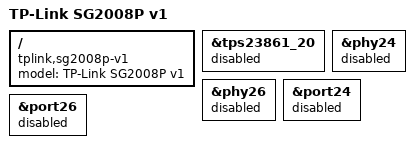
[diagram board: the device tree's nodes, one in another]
// SPDX-License-Identifier: GPL-2.0-or-later

#include "rtl8380_tplink_sg2xxx.dtsi"

/ {
	compatible = "tplink,sg2008p-v1", "realtek,rtl838x-soc";
	model = "TP-Link SG2008P v1";
};

&tps23861_20 {
	status = "disabled";
};

&phy24 {
	status = "disabled";
};

&phy26 {
	status = "disabled";
};

&port24 {
	status = "disabled";
};

&port26 {
	status = "disabled";
};
